# MCU_FSS0_CFG register map
Vendor: Texas Instruments
Peripheral module from a debugger description file (folder J7VCL).
Registers are 32-bit, access not given, reset values left out (the file's numbers can be read two ways) unless marked. A register's access mark holds for its fields unless they carry their own. Offsets are as the file gives them; lines under a group give offsets from that group; [hi:lo] are bit positions; {n}, {i} and the like mark numbered series; 'fields as' and 'values as' point back to an identical list; <NAME> marks a mode.

## MCU_FSS0_CFG
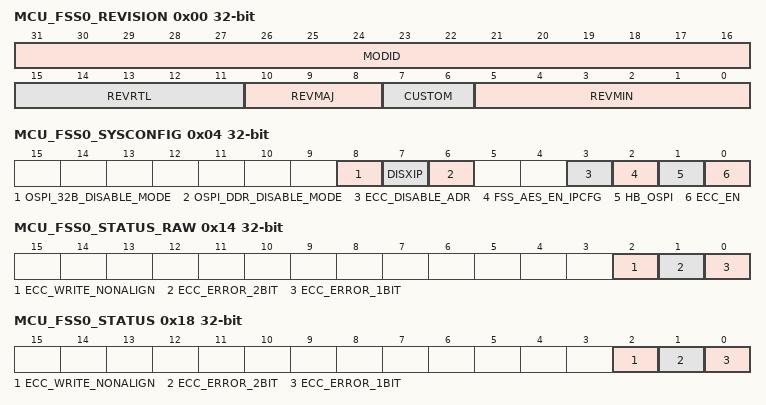
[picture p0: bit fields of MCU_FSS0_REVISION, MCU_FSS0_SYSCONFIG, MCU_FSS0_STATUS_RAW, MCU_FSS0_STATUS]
0x00 MCU_FSS0_REVISION ro — Revision Register Used by software to track features, bugs, and compatibility.
  [31:16] MODID — Module ID
  [15:11] REVRTL — RTL Revision
  [10:8] REVMAJ — Major Revision
  [7:6] CUSTOM
  [5:0] REVMIN — Minor Revision
0x04 MCU_FSS0_SYSCONFIG access per field — Configuration Register Controls various parameters of the cotroller state.
  [8] OSPI_32B_DISABLE_MODE rw — 0h = OSPI 32-bit mode enabled 1h = OSPI 32-bit mode disabled
  [7] DISXIP rw — 0h = XIP prefetch enabled 1h = XIP prefetch disabled
  [6] OSPI_DDR_DISABLE_MODE rw — 0h = OSPI DDR mode enabled 1h = OSPI DDR mode disabled
  [3] ECC_DISABLE_ADR rw — Block Address ECC Calculation 0h = Block address within ECC calculation 1h = Block address not within ECC calculation
  [2] FSS_AES_EN_IPCFG ro — Security Enable 0h = Disable security 1h = Enable security
  [1] HB_OSPI rw — Path Select 0h = Select OSPI path 1h = Select HyperBus interface path
  [0] ECC_EN rw — ECC Enable 0h = ECC disabled 1h = ECC enabled
0x10 MCU_FSS0_EOI access per field — End Of Interrupt (EOI) MISC Register The End Of Interrupt (EOI) MISC Register allows the CPU to acknowledge completion of an interrupt by writing to it for misc interrupt sources. An EOI write signal will be generated and another interrupt will be triggered if interrupt sources remain. This register will be reset one cycle after it has been written to. The EOI register is used to re-trigger the pulse interrupt signal to ensure that any nested interrupt events are serviced. The software interrupt handler must write to the EOI register at the end of the current interrupt processing routine, so that new events can re-trigger the pulse interrupt signal again. For level interrupt signals the EOI register is not functional and must not be used.
  [0] EOI_VECTOR rw — EOI Vector Write with bit position of targeted interrupt (example: external FSS ECC is bit 0). Upon write, level interrupt will clear and if un-serviced will issue another pulse interrupt.
0x14 MCU_FSS0_STATUS_RAW — Interrupt Source Set Register The Interrupt Source Set Register allows the interrupt sources to be manually set when writing 1h to a specific bit. Write 0h = No action Write 1h = Set event Read 0h = No event pending Read 1h = Event pending
  [2] ECC_WRITE_NONALIGN — ECC Write Non Aligned Write is not aligned to 32-byte boundary or not a multiple of 32-byte. (access RW1S)
  [1] ECC_ERROR_2BIT — ECC Error on 2 Bits Not correctable. (access RW1S)
  [0] ECC_ERROR_1BIT — ECC Error on 1 Bit Correctable. (access RW1S)
0x18 MCU_FSS0_STATUS — Interrupt Source Clear Register The Interrupt Source Clear Register allows the interrupt sources to be manually cleared when writing 1h to a specific bit. Write 0h = No action Write 1h = Clear event Read 0h = No event pending Read 1h = Event pending
  [2] ECC_WRITE_NONALIGN — ECC Write Non Aligned Write is not aligned to 32-byte boundary or not a multiple of 32-byte. (access RW1C)
  [1] ECC_ERROR_2BIT — ECC Error on 2 Bits Not correctable. (access RW1C)
  [0] ECC_ERROR_1BIT — ECC Error on 1 Bit Correctable. (access RW1C)
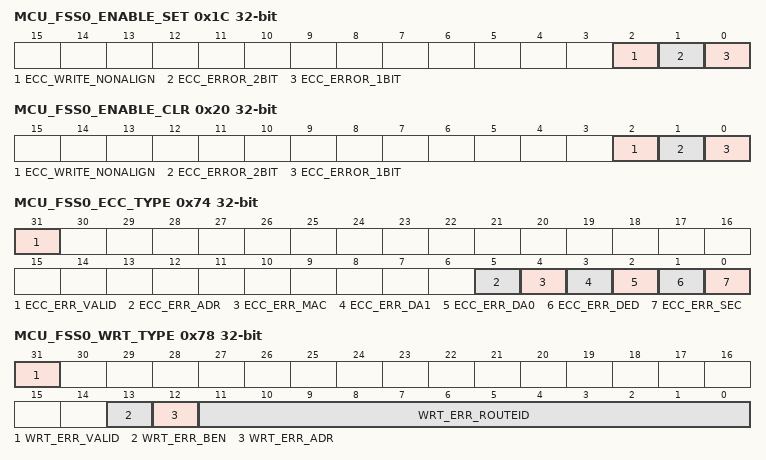
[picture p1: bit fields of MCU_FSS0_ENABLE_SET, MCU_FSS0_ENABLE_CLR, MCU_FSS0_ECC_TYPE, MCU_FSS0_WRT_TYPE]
0x1C MCU_FSS0_ENABLE_SET — Interrupt Source Enable Register The Interrupt Source Enable Register allows the interrupt sources to be manually enabled when writing 1h to a specific bit. Write 0h = No action Write 1h = Enable event Read 0h = Event is disabled Read 1h = Event is enabled
  fields as MCU_FSS0_STATUS_RAW
0x20 MCU_FSS0_ENABLE_CLR — Interrupt Source Disable Register The Interrupt Source Disable Register allows the interrupt sources to be manually disabled when writing 1h to a specific bit. Write 0h = No action Write 1h = Disable event Read 0h = Event is disabled Read 1h = Event is enabled
  fields as MCU_FSS0_STATUS
0x30 MCU_FSS0_ECC_RGSTRT_j access per field — ECC Region Start Register The ECC Region Start Register defines the start of the ECC region in 4 KB steps. Offset = 30h + (j × 8h); where j = 0h to 3h MCU_FSS0_ECC_RGSTRT_0: 4700 0030h MCU_FSS0_ECC_RGSTRT_1: 4700 0038h MCU_FSS0_ECC_RGSTRT_2: 4700 0046h MCU_FSS0_ECC_RGSTRT_3: 4700 0054h
  [19:0] R_START rw — ECC Region Start Address This bit field defines the start of the ECC region in 4 KB steps. Address start = {start[19:0], 000h} 0h = start is 0000 0000h 1h = start is 0000 1000h Ah = start is 0000 A000h
0x34 MCU_FSS0_ECC_RGSIZ_j access per field — ECC Region Size Register The ECC Region Size Register defines the size of the ECC region in 4 KB steps. Offset = 34h + (j × 8h); where j = 0h to 3h MCU_FSS0_ECC_RGSIZ_0: 4700 0034h MCU_FSS0_ECC_RGSIZ_1: 4700 0042h MCU_FSS0_ECC_RGSIZ_2: 4700 0050h MCU_FSS0_ECC_RGSIZ_3: 4700 0058h
  [19:0] R_SIZE rw — ECC Region Size This bit field defines the size of the ECC region in 4 KB steps. 0h = size is zero and disabled 1h = size is 4 KB Ah = size is 40 KB F FFFFh = size is 4 GB
0x70 MCU_FSS0_ECC_BLOCK_ADR ro — ECC Error Block Address Register The ECC Error Block Address Register holds the current top of stack ECC error block address, this is only valid when the [31] ECC_ERR_VALID bit is set.
  [31:5] ECC_ERROR_BLOCK_ADDR — ECC Error Block Address ECC 32-byte aligned block address
0x74 MCU_FSS0_ECC_TYPE — ECC Error Type Register The ECC Error Type Register holds the current top of stack ECC error info, this is only valid when the [31] ECC_ERR_VALID bit is set.
  [31] ECC_ERR_VALID — ECC Error Valid When set indicates that there is valid ECC error information available. Writing a 1h to this register will pop the top of the stack. (access RW1C)
  [5] ECC_ERR_ADR ro — ECC Error Address When set indicates that there was a single error detected within the address field.
  [4] ECC_ERR_MAC ro — ECC Error MAC When set indicates that there was a single error detected within the MAC field.
  [3] ECC_ERR_DA1 ro — ECC Error High Data Word When set indicates that there was a single error detected within the High Data word.
  [2] ECC_ERR_DA0 ro — ECC Error Low Data Word When set indicates that there was a single error detected within the Low Data word.
  [1] ECC_ERR_DED ro — ECC Error (DED) When set indicates that there was a double error detected for the block.
  [0] ECC_ERR_SEC ro — ECC Error (SEC) When set indicates that there was a single error detected for the block.
0x78 MCU_FSS0_WRT_TYPE — Error Write Type Register The Error Write Type Register holds the current top of stack write error info, this is only valid when the [31] WRT_ERR_VALID bit is set.
  [31] WRT_ERR_VALID — Write Error Valid When set indicates that there is valid write error information available. Writing a 1h to this register will pop the top of the stack. (access RW1C)
  [13] WRT_ERR_BEN ro — Write Error Non-Contiguous Byte Enables When set indicates that there was a write error due to a non-contiguous byte enables.
  [12] WRT_ERR_ADR ro — Write Error Address When set indicates that there was a write error due to a non-aligned address.
  [11:0] WRT_ERR_ROUTEID ro — Write Error Route ID Indicates the Route ID for the Master that caused the write error.
